# MCU_ADC12FC_16FFC0_COMMON_0_ADC12_FIFO_DMA register map
Vendor: Texas Instruments
Peripheral module from a debugger description file (folder J7_AHP).
Registers are 32-bit, read-only, reset 0x0 unless marked. A register's access mark holds for its fields unless they carry their own. Offsets are as the file gives them; lines under a group give offsets from that group; [hi:lo] are bit positions; {n}, {i} and the like mark numbered series; 'fields as' and 'values as' point back to an identical list; <NAME> marks a mode.

## MCU_ADC12FC_16FFC0_COMMON_0_ADC12_FIFO_DMA
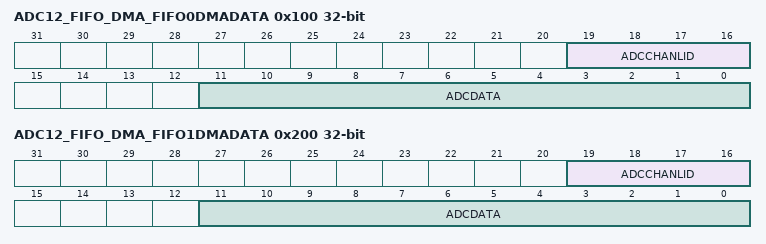
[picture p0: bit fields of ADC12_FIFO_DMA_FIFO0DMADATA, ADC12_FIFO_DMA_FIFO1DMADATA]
0x100 ADC12_FIFO_DMA_FIFO0DMADATA
  [19:16] ADCCHANLID — Optional ID tag of channel that captured the data. If tag option is disabled, these bits will be 0
  [11:0] ADCDATA — sampled ADC converted data value stored in FIFO
0x200 ADC12_FIFO_DMA_FIFO1DMADATA
  fields as ADC12_FIFO_DMA_FIFO0DMADATA
